LIN_description_file;
LIN_protocol_version = "2.1";
LIN_language_version = "2.1";
LIN_speed = 19.2 kbps;

Nodes {
  Master: IOv4MasterNode, 5 ms, 1 ms ;
  Slaves: VALVE_3WAY1, VALVE_3WAY2, VALVE_3WAY3, VALVE_3WAY4, VALVE_3WAY5, VALVE_3WAY6 ;
}

Signals {
  VALVE_3WAY1_ReqMovePos: 8, 8, IOv4MasterNode, VALVE_3WAY1 ;
  VALVE_3WAY2_ReqMovePos: 8, 8, IOv4MasterNode, VALVE_3WAY2 ;
  VALVE_3WAY3_ReqMovePos: 8, 8, IOv4MasterNode, VALVE_3WAY3 ;
  VALVE_3WAY4_ReqMovePos: 8, 8, IOv4MasterNode, VALVE_3WAY4 ;
  VALVE_3WAY5_ReqMovePos: 8, 8, IOv4MasterNode, VALVE_3WAY5 ;
  VALVE_3WAY6_ReqMovePos: 8, 8, IOv4MasterNode, VALVE_3WAY6 ;
  VALVE_3WAY1_MoveEnable: 1, 0, IOv4MasterNode, VALVE_3WAY1 ;
  VALVE_3WAY2_MoveEnable: 1, 0, IOv4MasterNode, VALVE_3WAY2 ;
  VALVE_3WAY3_MoveEnable: 1, 0, IOv4MasterNode, VALVE_3WAY3 ;
  VALVE_3WAY4_MoveEnable: 1, 0, IOv4MasterNode, VALVE_3WAY4 ;
  VALVE_3WAY5_MoveEnable: 1, 0, IOv4MasterNode, VALVE_3WAY5 ;
  VALVE_3WAY6_MoveEnable: 1, 0, IOv4MasterNode, VALVE_3WAY6 ;
  VALVE_3WAY1_RespPos: 8, 0, VALVE_3WAY1, IOv4MasterNode ;
  VALVE_3WAY1_MotorStatus: 1, 0, VALVE_3WAY1, IOv4MasterNode ;
  VALVE_3WAY1_TempWarn: 1, 0, VALVE_3WAY1, IOv4MasterNode ;
  VALVE_3WAY1_VoltageErr: 2, 0, VALVE_3WAY1, IOv4MasterNode ;
  VALVE_3WAY1_Fault_Signal: 4, 0, VALVE_3WAY1, IOv4MasterNode ;
  VALVE_3WAY1_Rsp_Comm_Err: 1, 0, VALVE_3WAY1, IOv4MasterNode ;
  VALVE_3WAY2_RespPos: 8, 0, VALVE_3WAY2, IOv4MasterNode ;
  VALVE_3WAY2_MotorStatus: 1, 0, VALVE_3WAY2, IOv4MasterNode ;
  VALVE_3WAY2_TempWarn: 1, 0, VALVE_3WAY2, IOv4MasterNode ;
  VALVE_3WAY2_VoltageErr: 2, 0, VALVE_3WAY2, IOv4MasterNode ;
  VALVE_3WAY2_Fault_Signal: 4, 0, VALVE_3WAY2, IOv4MasterNode ;
  VALVE_3WAY2_Rsp_Comm_Err: 1, 0, VALVE_3WAY2, IOv4MasterNode ;
  VALVE_3WAY3_RespPos: 8, 0, VALVE_3WAY3, IOv4MasterNode ;
  VALVE_3WAY3_MotorStatus: 1, 0, VALVE_3WAY3, IOv4MasterNode ;
  VALVE_3WAY3_TempWarn: 1, 0, VALVE_3WAY3, IOv4MasterNode ;
  VALVE_3WAY3_VoltageErr: 2, 0, VALVE_3WAY3, IOv4MasterNode ;
  VALVE_3WAY3_Fault_Signal: 4, 0, VALVE_3WAY3, IOv4MasterNode ;
  VALVE_3WAY3_Rsp_Comm_Err: 1, 0, VALVE_3WAY3, IOv4MasterNode ;
  VALVE_3WAY4_RespPos: 8, 0, VALVE_3WAY4, IOv4MasterNode ;
  VALVE_3WAY4_MotorStatus: 1, 0, VALVE_3WAY4, IOv4MasterNode ;
  VALVE_3WAY4_TempWarn: 1, 0, VALVE_3WAY4, IOv4MasterNode ;
  VALVE_3WAY4_VoltageErr: 2, 0, VALVE_3WAY4, IOv4MasterNode ;
  VALVE_3WAY4_Fault_Signal: 4, 0, VALVE_3WAY4, IOv4MasterNode ;
  VALVE_3WAY4_Rsp_Comm_Err: 1, 0, VALVE_3WAY4, IOv4MasterNode ;
  VALVE_3WAY5_RespPos: 8, 0, VALVE_3WAY5, IOv4MasterNode ;
  VALVE_3WAY5_MotorStatus: 1, 0, VALVE_3WAY5, IOv4MasterNode ;
  VALVE_3WAY5_TempWarn: 1, 0, VALVE_3WAY5, IOv4MasterNode ;
  VALVE_3WAY5_VoltageErr: 2, 0, VALVE_3WAY5, IOv4MasterNode ;
  VALVE_3WAY5_Fault_Signal: 4, 0, VALVE_3WAY5, IOv4MasterNode ;
  VALVE_3WAY5_Rsp_Comm_Err: 1, 0, VALVE_3WAY5, IOv4MasterNode ;
  VALVE_3WAY6_RespPos: 8, 0, VALVE_3WAY6, IOv4MasterNode ;
  VALVE_3WAY6_MotorStatus: 1, 0, VALVE_3WAY6, IOv4MasterNode ;
  VALVE_3WAY6_TempWarn: 1, 0, VALVE_3WAY6, IOv4MasterNode ;
  VALVE_3WAY6_VoltageErr: 2, 0, VALVE_3WAY6, IOv4MasterNode ;
  VALVE_3WAY6_Fault_Signal: 4, 0, VALVE_3WAY6, IOv4MasterNode ;
  VALVE_3WAY6_Rsp_Comm_Err: 1, 0, VALVE_3WAY6, IOv4MasterNode ;
}

Frames {
  VALVE_3WAY1_Cmd: 30, IOv4MasterNode, 8 {
    VALVE_3WAY1_ReqMovePos, 8 ;
    VALVE_3WAY1_MoveEnable, 0 ;
  }
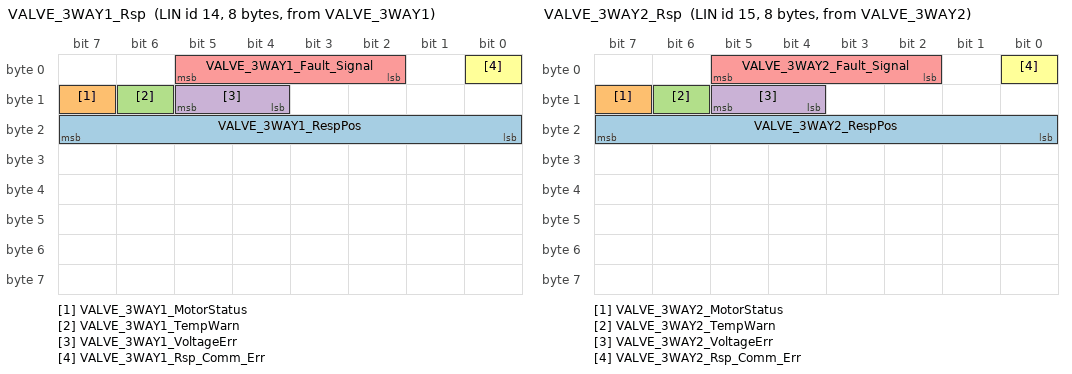
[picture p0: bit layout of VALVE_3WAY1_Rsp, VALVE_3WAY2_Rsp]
  VALVE_3WAY1_Rsp: 14, VALVE_3WAY1, 8 {
    VALVE_3WAY1_RespPos, 16 ;
    VALVE_3WAY1_MotorStatus, 15 ;
    VALVE_3WAY1_TempWarn, 14 ;
    VALVE_3WAY1_VoltageErr, 12 ;
    VALVE_3WAY1_Fault_Signal, 2 ;
    VALVE_3WAY1_Rsp_Comm_Err, 0 ;
  }
  VALVE_3WAY2_Cmd: 31, IOv4MasterNode, 8 {
    VALVE_3WAY2_ReqMovePos, 8 ;
    VALVE_3WAY2_MoveEnable, 0 ;
  }
  VALVE_3WAY2_Rsp: 15, VALVE_3WAY2, 8 {
    VALVE_3WAY2_RespPos, 16 ;
    VALVE_3WAY2_MotorStatus, 15 ;
    VALVE_3WAY2_TempWarn, 14 ;
    VALVE_3WAY2_VoltageErr, 12 ;
    VALVE_3WAY2_Fault_Signal, 2 ;
    VALVE_3WAY2_Rsp_Comm_Err, 0 ;
  }
  VALVE_3WAY3_Cmd: 32, IOv4MasterNode, 8 {
    VALVE_3WAY3_ReqMovePos, 8 ;
    VALVE_3WAY3_MoveEnable, 0 ;
  }
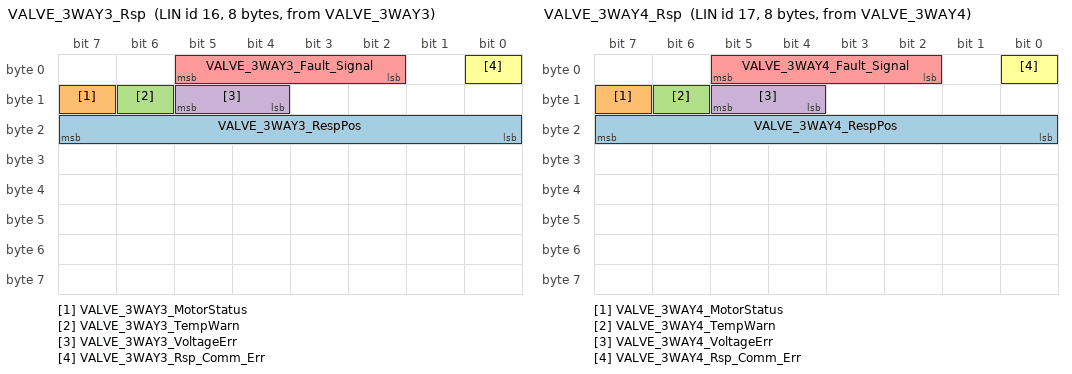
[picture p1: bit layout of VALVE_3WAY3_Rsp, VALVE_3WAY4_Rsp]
  VALVE_3WAY3_Rsp: 16, VALVE_3WAY3, 8 {
    VALVE_3WAY3_RespPos, 16 ;
    VALVE_3WAY3_MotorStatus, 15 ;
    VALVE_3WAY3_TempWarn, 14 ;
    VALVE_3WAY3_VoltageErr, 12 ;
    VALVE_3WAY3_Fault_Signal, 2 ;
    VALVE_3WAY3_Rsp_Comm_Err, 0 ;
  }
  VALVE_3WAY4_Cmd: 33, IOv4MasterNode, 8 {
    VALVE_3WAY4_ReqMovePos, 8 ;
    VALVE_3WAY4_MoveEnable, 0 ;
  }
  VALVE_3WAY4_Rsp: 17, VALVE_3WAY4, 8 {
    VALVE_3WAY4_RespPos, 16 ;
    VALVE_3WAY4_MotorStatus, 15 ;
    VALVE_3WAY4_TempWarn, 14 ;
    VALVE_3WAY4_VoltageErr, 12 ;
    VALVE_3WAY4_Fault_Signal, 2 ;
    VALVE_3WAY4_Rsp_Comm_Err, 0 ;
  }
  VALVE_3WAY5_Cmd: 34, IOv4MasterNode, 8 {
    VALVE_3WAY5_ReqMovePos, 8 ;
    VALVE_3WAY5_MoveEnable, 0 ;
  }
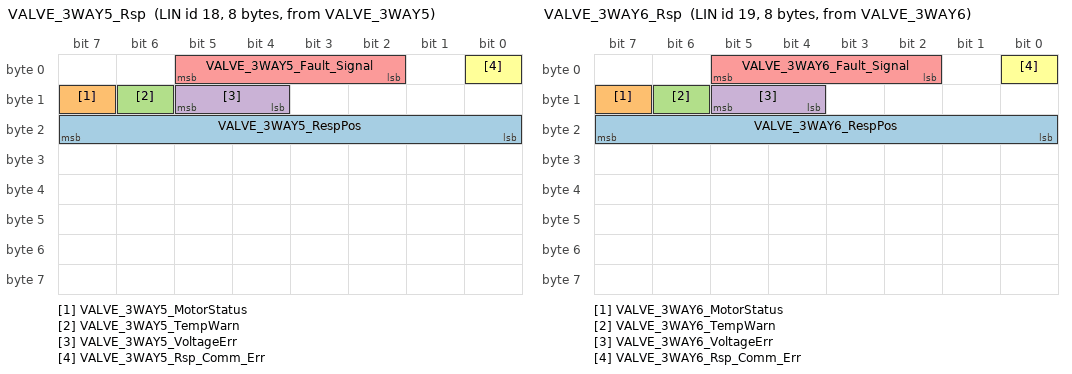
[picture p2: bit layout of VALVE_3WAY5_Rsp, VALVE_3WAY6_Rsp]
  VALVE_3WAY5_Rsp: 18, VALVE_3WAY5, 8 {
    VALVE_3WAY5_RespPos, 16 ;
    VALVE_3WAY5_MotorStatus, 15 ;
    VALVE_3WAY5_TempWarn, 14 ;
    VALVE_3WAY5_VoltageErr, 12 ;
    VALVE_3WAY5_Fault_Signal, 2 ;
    VALVE_3WAY5_Rsp_Comm_Err, 0 ;
  }
  VALVE_3WAY6_Cmd: 35, IOv4MasterNode, 8 {
    VALVE_3WAY6_ReqMovePos, 8 ;
    VALVE_3WAY6_MoveEnable, 0 ;
  }
  VALVE_3WAY6_Rsp: 19, VALVE_3WAY6, 8 {
    VALVE_3WAY6_RespPos, 16 ;
    VALVE_3WAY6_MotorStatus, 15 ;
    VALVE_3WAY6_TempWarn, 14 ;
    VALVE_3WAY6_VoltageErr, 12 ;
    VALVE_3WAY6_Fault_Signal, 2 ;
    VALVE_3WAY6_Rsp_Comm_Err, 0 ;
  }
}

Node_attributes {
  VALVE_3WAY1{
    LIN_protocol = "2.1" ;
    configured_NAD = 0xC4 ;
    initial_NAD = 0xC4 ;
    product_id = 0x124, 0xFFFE, 0 ;
    response_error = VALVE_3WAY1_Rsp_Comm_Err ;
    P2_min = 50 ms ;
    ST_min = 0 ms ;
    N_As_timeout = 1000 ms ;
    N_Cr_timeout = 1000 ms ;
    configurable_frames {
      VALVE_3WAY1_Cmd ;
      VALVE_3WAY1_Rsp ;
    }
  }
  VALVE_3WAY2{
    LIN_protocol = "2.1" ;
    configured_NAD = 0xC4 ;
    initial_NAD = 0xC4 ;
    product_id = 0x124, 0xFFFE, 0 ;
    response_error = VALVE_3WAY2_Rsp_Comm_Err ;
    P2_min = 50 ms ;
    ST_min = 0 ms ;
    N_As_timeout = 1000 ms ;
    N_Cr_timeout = 1000 ms ;
    configurable_frames {
      VALVE_3WAY2_Cmd ;
      VALVE_3WAY2_Rsp ;
    }
  }
  VALVE_3WAY3{
    LIN_protocol = "2.1" ;
    configured_NAD = 0xC4 ;
    initial_NAD = 0xC4 ;
    product_id = 0x124, 0xFFFE, 0 ;
    response_error = VALVE_3WAY3_Rsp_Comm_Err ;
    P2_min = 50 ms ;
    ST_min = 0 ms ;
    N_As_timeout = 1000 ms ;
    N_Cr_timeout = 1000 ms ;
    configurable_frames {
      VALVE_3WAY3_Cmd ;
      VALVE_3WAY3_Rsp ;
    }
  }
  VALVE_3WAY4{
    LIN_protocol = "2.1" ;
    configured_NAD = 0xC4 ;
    initial_NAD = 0xC4 ;
    product_id = 0x124, 0xFFFE, 0 ;
    response_error = VALVE_3WAY4_Rsp_Comm_Err ;
    P2_min = 50 ms ;
    ST_min = 0 ms ;
    N_As_timeout = 1000 ms ;
    N_Cr_timeout = 1000 ms ;
    configurable_frames {
      VALVE_3WAY4_Cmd ;
      VALVE_3WAY4_Rsp ;
    }
  }
  VALVE_3WAY5{
    LIN_protocol = "2.1" ;
    configured_NAD = 0xC4 ;
    initial_NAD = 0xC4 ;
    product_id = 0x124, 0xFFFE, 0 ;
    response_error = VALVE_3WAY5_Rsp_Comm_Err ;
    P2_min = 50 ms ;
    ST_min = 0 ms ;
    N_As_timeout = 1000 ms ;
    N_Cr_timeout = 1000 ms ;
    configurable_frames {
      VALVE_3WAY5_Cmd ;
      VALVE_3WAY5_Rsp ;
    }
  }
  VALVE_3WAY6{
    LIN_protocol = "2.1" ;
    configured_NAD = 0xC4 ;
    initial_NAD = 0xC4 ;
    product_id = 0x124, 0xFFFE, 0 ;
    response_error = VALVE_3WAY6_Rsp_Comm_Err ;
    P2_min = 50 ms ;
    ST_min = 0 ms ;
    N_As_timeout = 1000 ms ;
    N_Cr_timeout = 1000 ms ;
    configurable_frames {
      VALVE_3WAY6_Cmd ;
      VALVE_3WAY6_Rsp ;
    }
  }
}

Schedule_tables {
 LinScheduleTable01 {
    VALVE_3WAY1_Cmd delay 20 ms ;
    VALVE_3WAY1_Rsp delay 20 ms ;
  }
 LinScheduleTable02 {
    VALVE_3WAY2_Cmd delay 20 ms ;
    VALVE_3WAY2_Rsp delay 20 ms ;
  }
 LinScheduleTable03 {
    VALVE_3WAY3_Cmd delay 20 ms ;
    VALVE_3WAY3_Rsp delay 20 ms ;
   }
 LinScheduleTable04 {
  VALVE_3WAY4_Cmd delay 20 ms ;
    VALVE_3WAY4_Rsp delay 20 ms ;
  }
 LinScheduleTable05 {
    VALVE_3WAY5_Cmd delay 20 ms ;
    VALVE_3WAY5_Rsp delay 20 ms ;
  }
 LinScheduleTable06 {
    VALVE_3WAY6_Cmd delay 20 ms ;
    VALVE_3WAY6_Rsp delay 20 ms ;
  }
}

Signal_encoding_types {
  ReqMovePos_Encoding {
    physical_value, 0, 255, 0.393, 0, "%" ;
  }
  MotorStatus_Encoding {
    logical_value, 0, "Motor Stop" ;
    logical_value, 1, "Motor Running" ;
  }
  Fault_Signal_Encoding {
    logical_value, 0, "No Fault" ;
    logical_value, 1, "Coil_Open Detected" ;
    logical_value, 2, "Stall Detected" ;
    logical_value, 3, "OverTemp Shutdown" ;
    logical_value, 4, "Coil Short Detected" ;
  }
  Pos_Encoding {
    physical_value, 0, 255, 0.393, 0, "%" ;
  }
  Rsp_Comm_Err_Encoding {
    logical_value, 0, "No Error" ;
    logical_value, 1, "LIN Communication Error" ;
  }
  TempWarn_Encoding {
    logical_value, 0, "No Error" ;
    logical_value, 1, "Temperature Warning" ;
  }
  VoltageErr_Encoding {
    logical_value, 0, "No Error" ;
    logical_value, 1, "overvoltage" ;
    logical_value, 2, "lackvoltage" ;
  }
  MoveEnable_Encoding {
    logical_value, 0, "NoReq" ;
    logical_value, 1, "ReqMotorMove" ;
  }
}

Signal_representation {
  Fault_Signal_Encoding: VALVE_3WAY1_Fault_Signal, VALVE_3WAY2_Fault_Signal, VALVE_3WAY3_Fault_Signal, VALVE_3WAY4_Fault_Signal, VALVE_3WAY5_Fault_Signal, VALVE_3WAY6_Fault_Signal ;
  MotorStatus_Encoding: VALVE_3WAY1_MotorStatus, VALVE_3WAY2_MotorStatus, VALVE_3WAY3_MotorStatus, VALVE_3WAY4_MotorStatus, VALVE_3WAY5_MotorStatus, VALVE_3WAY6_MotorStatus ;
  Pos_Encoding: VALVE_3WAY1_RespPos, VALVE_3WAY2_RespPos, VALVE_3WAY3_RespPos, VALVE_3WAY4_RespPos, VALVE_3WAY5_RespPos, VALVE_3WAY6_RespPos ;
  ReqMovePos_Encoding: VALVE_3WAY1_ReqMovePos, VALVE_3WAY2_ReqMovePos, VALVE_3WAY3_ReqMovePos, VALVE_3WAY4_ReqMovePos, VALVE_3WAY5_ReqMovePos, VALVE_3WAY6_ReqMovePos ;
  Rsp_Comm_Err_Encoding: VALVE_3WAY1_Rsp_Comm_Err, VALVE_3WAY2_Rsp_Comm_Err, VALVE_3WAY3_Rsp_Comm_Err, VALVE_3WAY4_Rsp_Comm_Err, VALVE_3WAY5_Rsp_Comm_Err, VALVE_3WAY6_Rsp_Comm_Err ;
  TempWarn_Encoding: VALVE_3WAY1_TempWarn, VALVE_3WAY2_TempWarn, VALVE_3WAY3_TempWarn, VALVE_3WAY4_TempWarn, VALVE_3WAY5_TempWarn, VALVE_3WAY6_TempWarn ;
  VoltageErr_Encoding: VALVE_3WAY1_VoltageErr, VALVE_3WAY2_VoltageErr, VALVE_3WAY3_VoltageErr, VALVE_3WAY4_VoltageErr, VALVE_3WAY5_VoltageErr, VALVE_3WAY6_VoltageErr ;
}
